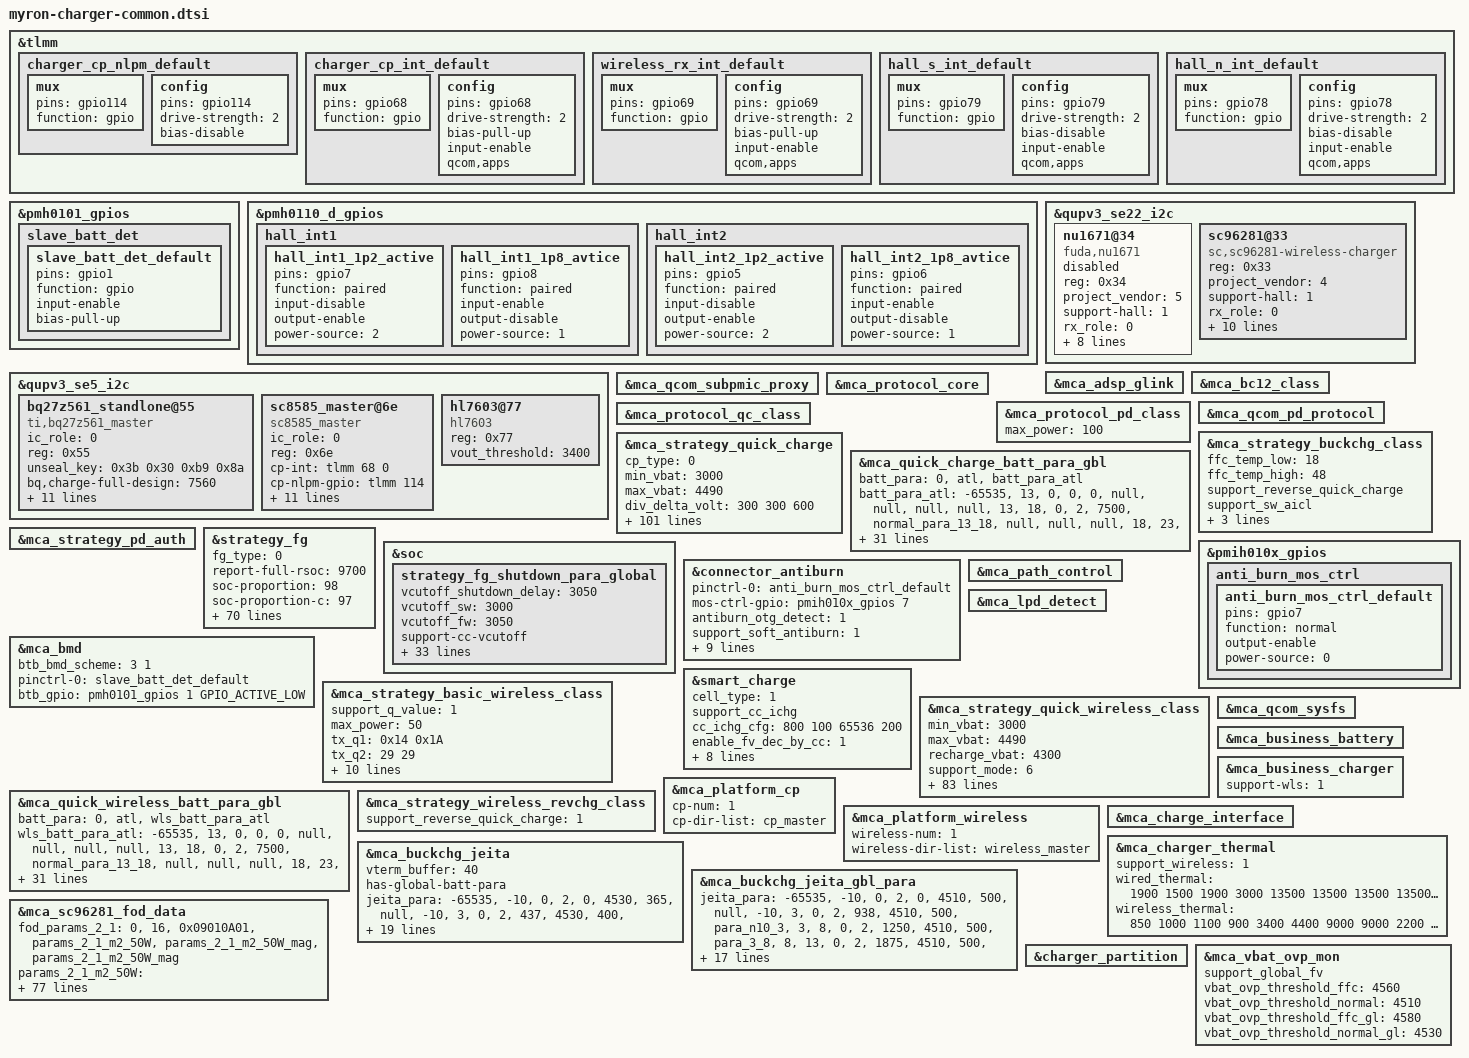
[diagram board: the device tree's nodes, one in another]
#include "mca.dtsi"

&tlmm {
	charger_cp_nlpm_default: charger_cp_nlpm_default {
		mux {
			pins = "gpio114";
			function = "gpio";
		};
		config {
			pins = "gpio114";
			drive-strength = <2>;   /* 2 mA */
			bias-disable;
		};
	};

	charger_cp_int_default: charger_cp_int_default {
		mux {
			pins = "gpio68";
			function = "gpio";
		};
		config {
			pins = "gpio68";
			drive-strength = <2>;   /* 2 mA */
			bias-pull-up;
			input-enable;
			qcom,apps;
		};
	};

	wireless_rx_int_default: wireless_rx_int_default {
		mux {
			pins = "gpio69";
			function = "gpio";
		};

		config {
			pins = "gpio69";
			drive-strength = <2>;
			bias-pull-up;
			input-enable;
			qcom,apps;
		};
	};

	hall_s_int_default: hall_s_int_default {
		mux {
			pins = "gpio79";
			function = "gpio";
		};

		config {
			pins = "gpio79";
			drive-strength = <2>;
			bias-disable;
			input-enable;
			qcom,apps;
		};
	};

	hall_n_int_default: hall_n_int_default {
		mux {
			pins = "gpio78";
			function = "gpio";
		};

		config {
			pins = "gpio78";
			drive-strength = <2>;
			bias-disable;
			input-enable;
			qcom,apps;
		};
	};

};

&pmh0101_gpios {
	slave_batt_det {
		slave_batt_det_default: slave_batt_det_default {
			pins = "gpio1";
			function = "gpio";
			input-enable;
			bias-pull-up;
		};
	};
};

&pmh0110_d_gpios {
	hall_int1 {
		hall_int1_1p2_active: hall_int1_1p2_active {
			pins = "gpio7";
			function = "paired";
			input-disable;
			output-enable;
			power-source = <2>; /* 1.2v */
		};

		hall_int1_1p8_avtice:hall_int1_1p8_avtice {
			pins = "gpio8";
			function = "paired";
			input-enable;
			output-disable;
			power-source = <1>; /* 1.8v */
		};
	};

	hall_int2 {
		hall_int2_1p2_active: hall_int2_1p2_active {
			pins = "gpio5";
			function = "paired";
			input-disable;
			output-enable;
			power-source = <2>; /* 1.2v */
		};

		hall_int2_1p8_avtice:hall_int2_1p8_avtice {
			pins = "gpio6";
			function = "paired";
			input-enable;
			output-disable;
			power-source = <1>; /* 1.8v */
		};
	};
};


&qupv3_se5_i2c {
	status = "ok";
	#address-cells = <1>;
	#size-cells = <0>;
	bq27z561_standlone@55 {
		compatible = "ti,bq27z561_master";
		ic_role = <0>;
		reg = <0x55>;
		unseal_key = /bits/ 8 <0x3b 0x30 0xb9 0x8a>;
		bq,charge-full-design = <7560>;
		soh_th = <92>;
		cycle_th = <400>;
		cycle_step = <50>;
		resistance-id = <100000>;
		support_batt_manager_4p0;
		base_termv = <3030>;
		base_termv_gl = <3200>;
		delta_soh_compesation = <
			0 0
			50 2
			100 5
			150 7
			200 9
			250 12
			300 15
			350 18
			400 18
			450 18
			500 18>;
		delta_soh_compesation_gl = <
			0 0
			50 1
			100 2
			150 4
			200 5
			250 5
			300 5
			350 5
			400 5
			450 5
			500 5>;
		status = "ok";
	};

	sc8585_master@6e {
		compatible = "sc8585_master";
		status = "ok";
		ic_role = <0>;
		reg = <0x6e>;
		cp-int= <&tlmm 68 0>;
		cp-nlpm-gpio = <&tlmm 114 0x00>;
		pinctrl-names = "default";
		pinctrl-0 = <&charger_cp_nlpm_default>, <&charger_cp_int_default>;
		bat-ovp-threshold = <4700>;
		bat-ovp-alarm-threshold = <4650>;
		bus-ovp-threshold = <21000 12000 6000>;
		usb-ovp-threshold = <21000 14000 7500>;
		bus-ocp-threshold = <5000 5500 5000>;
		wpc-ovp-threshold = <21000>;
		out-ovp-threshold = <5000>;
		pmid2-uvp-threshold = <350 350 100>;
		pmid2-ovp-threshold = <600>;
	};

	hl7603@77 {
		compatible = "hl7603";
		reg = <0x77>;
		vout_threshold = <3400>;
	};
};

&qupv3_se22_i2c {
	status = "ok";
	#address-cells = <1>;
	#size-cells = <0>;

	nu1671@34 {
		status = "disabled";
		compatible = "fuda,nu1671";
		reg = <0x34>;
		project_vendor = <5>;
		support-hall = <1>;
		rx_role = <0>;
		fw_version_index = <0>;
		pinctrl-names = "default";
		pinctrl-0 = <&wireless_rx_int_default>, <&hall_s_int_default>, <&hall_n_int_default>;
		rx-int = <&tlmm 69 0x00>;
		pwr-det-int = <&tlmm 57 0x00>;
		sleep-rx-gpio = <&tlmm 200 0x00>;
		hall-s-int = <&tlmm 79 0x00>;
		hall-n-int = <&tlmm 78 0x00>;
	};

	sc96281@33 {
		compatible = "sc,sc96281-wireless-charger";
		reg = <0x33>;
		project_vendor = <4>;
		support-hall = <1>;
		rx_role = <0>;
		fw_version_index = <1>;
		pinctrl-names = "default";
		pinctrl-0 = <&wireless_rx_int_default>, <&hall_s_int_default>, <&hall_n_int_default>,
					<&hall_int1_1p2_active>, <&hall_int1_1p8_avtice>,
					<&hall_int2_1p2_active>, <&hall_int2_1p8_avtice>;
		rx-int = <&tlmm 69 0x00>;
		pwr-det-int = <&tlmm 57 0x00>;
		sleep-rx-gpio = <&tlmm 200 0x00>;
		hall-s-int = <&tlmm 79 0x00>;
		hall-n-int = <&tlmm 78 0x00>;
	};
};

&mca_adsp_glink {
	status = "ok";
};

&mca_bc12_class {
	status = "ok";
};

&mca_qcom_subpmic_proxy {
	status = "ok";
};

&mca_protocol_core {
	status = "ok";
};

&mca_protocol_pd_class {
	status = "ok";
	max_power = <100>;
};

&mca_qcom_pd_protocol {
	status = "ok";
};

&mca_protocol_qc_class {
	status = "ok";
};


&mca_strategy_buckchg_class {
	status = "ok";
	ffc_temp_low = <18>;
	ffc_temp_high = <48>;
	support_reverse_quick_charge;
	support_sw_aicl;
	support_revchg_screenon;
	support_pps_100w = <3>;
	pd_authing_default_icl;
};

&mca_strategy_quick_charge {
	status = "ok";
	cp_type = <0>;
	min_vbat = <3000>;
	max_vbat = <4490>;
	div_delta_volt = <300 300 600>;
	div_single_curr = <4500 11000 18400>;
	div_max_curr = <5000 12000 18400>;
	non_mi_pps_max_curr = <4500 11000 18400>;
	support_mode = <6>;
	has-global-batt-para;
	support_cp_vfc = <1>;
	real_curr_max = <17500>;
	support_monitor_current = <17600>;
	curr_monitor_time_s = <120>;
	support_cancel_compensation;
	max_vbat_threshold = <4580>;
	en_buck_parallel_chg = <1>;
	buck_icl_fcc_curr = <1000 3000>;
	buck_en_th = <13000 2500>;
	buck_dis_th = <13000 3850>;

	/* volt_ratio, cur_gap, vbat_gap, vstep_ratio */
	vstep_para =
		"1", "300", "2000", "0", "2",
		"2", "300", "2000", "0", "4",
		"4", "300", "8000", "0", "25",
		"4", "300", "4000", "20", "17",
		"4", "300", "2000", "10", "8",
		"4", "300", "1200", "10", "5",
		"4", "300", "800", "0", "2",
		"1", "800", "2000", "0", "2",
		"2", "800", "2000", "0", "4",
		"4", "800", "8000", "0", "10",
		"4", "800", "6000", "0", "5",
		"4", "800", "4000", "0", "2";

	batt_para =
		"0", "atl", "batt_para_atl",
		"0", "coslight", "batt_para_cos";
	/* temp_low, temp_high, low_hys, high_hys, max_curr, normal_para, ffc_para, normal_stage, ffc_stage */
	batt_para_atl =
		"-65535", "13", "0", "0", "0", "null", "null", "null", "null",
		"13", "18", "0", "2", "4374", "normal_para_atl_13_18", "null", "null", "null",
		"18", "23", "0", "1", "12400", "normal_para_atl_18_23", "ffc_para_atl_18_23", "null", "ffc_stage_atl_18_23",
		"23", "35", "0", "0", "18400", "normal_para_atl_23_35", "ffc_para_atl_23_35", "null", "ffc_stage_atl_23_35",
		"35", "40", "1", "0", "18400", "normal_para_atl_35_40", "ffc_para_atl_35_40", "null", "ffc_stage_atl_35_40",
		"40", "48", "1", "0", "18400", "normal_para_atl_40_48", "ffc_para_atl_40_48", "null", "ffc_stage_atl_40_48",
		"48", "65535", "2", "0", "0", "null", "null", "null", "null";

	/* volt, curr_max, curr_min */
	normal_para_atl_13_18 =
		"4200", "4374", "2916",
		"4525", "2916", "365";

	normal_para_atl_18_23 =
		"4250", "12400", "8748",
		"4505", "8748", "365";
	ffc_para_atl_18_23 =
		"4250", "12400", "10935",
		"4500", "10935", "8748",
		"4555", "8748", "1094";
	ffc_stage_atl_18_23 = <0 0 0 0 0 0>;

	normal_para_atl_23_35 =
		"4190", "18400", "8748",
		"4505", "8748", "365";
	ffc_para_atl_23_35 =
		"4190", "18400", "12400",
		"4290", "12400", "10935",
		"4500", "10935", "8748",
		"4555", "8748", "1458";
	ffc_stage_atl_23_35 = <0 1 0 0 0 0 0 0>;

	normal_para_atl_35_40 =
		"4190", "18400", "8748",
		"4495", "8748", "365";
	ffc_para_atl_35_40 =
		"4190", "18400", "12400",
		"4290", "12400", "10935",
		"4500", "10935", "8748",
		"4555", "8748", "2333";
	ffc_stage_atl_35_40 = <0 1 0 0 0 0 0 0>;

	normal_para_atl_40_48 =
		"4190", "18400", "8748",
		"4485", "8748", "365";
	ffc_para_atl_40_48 =
		"4190", "18400", "12400",
		"4290", "12400", "10935",
		"4500", "10935", "8748",
		"4555", "8748", "3208";
	ffc_stage_atl_40_48 = <0 1 0 0 0 0 0 0>;

	batt_para_cos =
		"-65535", "13", "0", "0", "0", "null", "null", "null", "null",
		"13", "18", "0", "2", "4386", "normal_para_cos_13_18", "null", "null", "null",
		"18", "23", "0", "1", "12400", "normal_para_cos_18_23", "ffc_para_cos_18_23", "null", "ffc_stage_cos_18_23",
		"23", "35", "0", "0", "18400", "normal_para_cos_23_35", "ffc_para_cos_23_35", "null", "ffc_stage_cos_23_35",
		"35", "40", "1", "0", "18400", "normal_para_cos_35_40", "ffc_para_cos_35_40", "null", "ffc_stage_cos_35_40",
		"40", "48", "1", "0", "18400", "normal_para_cos_40_48", "ffc_para_cos_40_48", "null", "ffc_stage_cos_40_48",
		"48", "65535", "2", "0", "0", "null", "null", "null", "null";
	/* volt, curr_max, curr_min */
	normal_para_cos_13_18 =
		"4200", "4386", "2924",
		"4525", "2924", "366";

	normal_para_cos_18_23 =
		"4250", "12400", "8772",
		"4505", "8772", "366";
	ffc_para_cos_18_23 =
		"4250", "12400", "10965",
		"4500", "10965", "8772",
		"4555", "8772", "810";
	ffc_stage_cos_18_23 = <0 0 0 0 0 0>;

	normal_para_cos_23_35 =
		"4290", "18400", "8772",
		"4505", "8772", "366";
	ffc_para_cos_23_35 =
		"4290", "18400", "12400",
		"4350", "12400", "10965",
		"4500", "10965", "8772",
		"4555", "8772", "1023";
	ffc_stage_cos_23_35 = <0 1 0 0 0 0 0 0>;

	normal_para_cos_35_40 =
		"4290", "18400", "8772",
		"4495", "8772", "366";
	ffc_para_cos_35_40 =
		"4290", "18400", "12400",
		"4350", "12400", "10965",
		"4500", "10965", "8772",
		"4555", "8772", "1608";
	ffc_stage_cos_35_40 = <0 1 0 0 0 0 0 0>;

	normal_para_cos_40_48 =
		"4290", "18400", "8772",
		"4485", "8772", "366";
	ffc_para_cos_40_48 =
		"4290", "18400", "12400",
		"4350", "12400", "10965",
		"4500", "10965", "8772",
		"4555", "8772", "2339";
	ffc_stage_cos_40_48 = <0 1 0 0 0 0 0 0>;
};

&mca_quick_charge_batt_para_gbl {
	batt_para =
		"0", "atl", "batt_para_atl";
	/* temp_low, temp_high, low_hys, high_hys, max_curr, normal_para, ffc_para, normal_stage, ffc_stage */
	batt_para_atl =
		"-65535", "13", "0", "0", "0", "null", "null", "null", "null",
		"13", "18", "0", "2", "7500", "normal_para_13_18", "null", "null", "null",
		"18", "23", "0", "1", "12500", "normal_para_18_23", "null", "null", "null",
		"23", "35", "0", "0", "18000", "normal_para_23_35", "ffc_para_23_35", "null", "ffc_stage_23_35",
		"35", "40", "1", "0", "18000", "normal_para_35_40", "ffc_para_35_40", "null", "ffc_stage_35_40",
		"40", "48", "1", "0", "18000", "normal_para_40_48", "ffc_para_40_48", "null", "ffc_stage_40_48",
		"48", "65535", "2", "0", "0", "null", "null", "null", "null";

	/* volt, curr_max, curr_min */
	normal_para_13_18 =
		"4200", "7500", "6250",
		"4505", "6250", "500";

	normal_para_18_23 =
		"4200", "12500", "9375",
		"4505", "9375", "500";

	normal_para_23_35 =
		"4150", "18000", "7500",
		"4505", "7500", "500";
	ffc_para_23_35 =
		"4150", "18000", "12400",
		"4350", "12400", "11250",
		"4400", "11250", "9375",
		"4500", "9375", "7500",
		"4555", "7500", "2500";
	ffc_stage_23_35 = <0 0 0 0 0 0 0 0 0 0>;

	normal_para_35_40 =
		"4150", "18000", "7500",
		"4475", "7500", "500";
	ffc_para_35_40 =
		"4150", "18000", "12400",
		"4350", "12400", "11250",
		"4400", "11250", "9375",
		"4500", "9375", "7500",
		"4555", "7500", "3562";
	ffc_stage_35_40 = <0 0 0 0 0 0 0 0 0 0>;

	normal_para_40_48 =
		"4150", "18000", "7500",
		"4465", "7500", "500";
	ffc_para_40_48 =
		"4150", "18000", "12400",
		"4350", "12400", "11250",
		"4400", "11250", "9375",
		"4500", "9375", "7500",
		"4555", "7500", "5000";
	ffc_stage_40_48 = <0 0 0 0 0 0 0 0 0 0>;
};

&mca_strategy_pd_auth {
	status = "ok";
};

&strategy_fg {
	status = "ok";
	fg_type = <0>;
	report-full-rsoc = <9700>;
	soc-proportion = <98>;
	soc-proportion-c = <97>;
	support-pnc;
	support-vpack-low-shutdown;
	has_global_shutdown_para;
	vcutoff_shutdown_delay = <3030>;
	vcutoff_sw = <2980>;
	vcutoff_fw = <3030>;
	vterm_delta = <7>;

	support-cc-vcutoff;
	/* temp_low, temp_high, low_temp_hys, high_temp_hys, vterm_para_name */
	cc_vcutoff_cfg =
		"-65535", "-6", "0", "2", "cc_para0",
		"-6", "0", "2", "2", "cc_para1",
		"0", "10", "2", "2", "cc_para2",
		"10", "60", "2", "0", "cc_para3",
		"60", "65535", "2", "0", "cc_para4";
	/* cycle_count, vterm_fw, vterm_shutdown_delay, vempty */
	cc_para0 =
		"400", "2650", "2600", "2500",
		"800", "2700", "2650", "2600",
		"1200", "2850", "2800", "2750",
		"65535", "2950", "2900", "2850";
	cc_para1 =
		"400", "2700", "2650", "2600",
		"800", "2850", "2800", "2750",
		"1200", "2950", "2900", "2850",
		"65535", "3050", "3000", "2950";
	cc_para2 =
		"400", "2850", "2850", "2800",
		"800", "2950", "2950", "2900",
		"1200", "3000", "3000", "2950",
		"65535", "3100", "3100", "3050";
	cc_para3 =
		"400", "3030", "3030", "2980",
		"800", "3130", "3130", "3080",
		"1200", "3200", "3200", "3150",
		"65535", "3260", "3260", "3210";
	cc_para4 =
		"65535", "3260", "3260", "3210";

	support-dod-vcutoff-v2;
	weight = <20 18 15>;
	/* temp_low, temp_high, low_temp_hys, high_temp_hys, vterm_para_name */
	dod_vcutoff_cfg =
		"-65535", "-6", "0", "2", "dod_para0",
		"-6", "0", "2", "2", "dod_para1",
		"0", "10", "2", "2", "dod_para2",
		"10", "60", "2", "0", "dod_para3",
		"60", "65535", "2", "0", "dod_para4";
	/* dod_count, vterm_fw, vterm_shutdown_delay, vempty */
	dod_para0 =
		"79", "2650", "2600", "2500",
		"159", "2700", "2650", "2600",
		"413", "2850", "2800", "2750",
		"1050", "2950", "2900", "2850",
		"65535", "3050", "3000", "2950";
	dod_para1 =
		"79", "2700", "2650", "2600",
		"159", "2850", "2800", "2750",
		"413", "2950", "2900", "2850",
		"1050", "3050", "3000", "2950",
		"65535", "3150", "3100", "3050";
	dod_para2 =
		"79", "2850", "2850", "2800",
		"159", "2950", "2950", "2900",
		"413", "3000", "3000", "2950",
		"1050", "3100", "3100", "3050",
		"65535", "3200", "3200", "3150";
	dod_para3 =
		"79", "3030", "3030", "2980",
		"159", "3130", "3130", "3080",
		"413", "3200", "3200", "3150",
		"1050", "3260", "3260", "3210",
		"65535", "3310", "3310", "3260";
	dod_para4 =
		"65535", "3310", "3310", "3260";

	adapt_power = <100>;
	model-name = "P11U_7560mah_100w";
	model-name-global = "P11U_6500mah_100w";
	support_full_design_gl;
	charge-full-design = <7560>;
	capacity_comp = <0>;
	capacity_comp_gl = <0>;
	support_dynamic_capacity_comp;
	support_dtpt = <1>;
	charge-full-design-gl = <6500>;
	fg_hightemp_vterm = <4200>;
	support-lossless-rechg = <1>;
	lossless_rechg_cfg = <18 47 90>;
	support_normal_force_full;
	normal_force_full_hys = <116>;
	suppot_RSOC_0_smooth = <1>;
	smooth_temp_unit = <0 150>; //15℃
	smooth_curr_unit = <0 300000 600000 1000000 >;
	smooth_vol_offset = <0x80000000 0 100 200 300 >;
	dischg_smooth_low_temp_unit = <
		10 10 10 10
		20 10 10 10
		40 20 10 10
		80 40 30 20
		150 80 70 50 >;
	dischg_smooth_high_temp_unit = <
		10 10 10 10
		30 20 10 10
		60 40 20 10
		150 70 50 40
		200 150 100 70 >;
	extreme_cold_temp_compemsation =
		"100", "50", "50",
		"100", "350", "65",
		"350", "350", "80",
		"2147483647", "150", "100";
};

&soc {
	strategy_fg_shutdown_para_global {
		vcutoff_shutdown_delay = <3050>;
		vcutoff_sw = <3000>;
		vcutoff_fw = <3050>;
		support-cc-vcutoff;
		/* temp_low, temp_high, low_temp_hys, high_temp_hys, vterm_para_name */
		cc_vcutoff_cfg =
			"-65535", "-6", "0", "2", "cc_para0",
			"-6", "0", "2", "2", "cc_para1",
			"0", "10", "2", "2", "cc_para2",
			"10", "60", "2", "0", "cc_para3",
			"60", "65535", "2", "0", "cc_para4";
		/* cycle_count, vterm_fw, vterm_shutdown_delay, vempty */
		cc_para0 =
			"600", "2900", "2850", "2800",
			"1200", "2900", "2850", "2800",
			"65535", "3000", "2950","2900";
		cc_para1 =
			"600", "2900", "2850", "2800",
			"1200", "2900", "2850","2800",
			"65535", "3050", "3000", "2950";
		cc_para2 =
			"600", "2950", "2950", "2900",
			"1200", "3050", "3050", "3000",
			"65535", "3150", "3150", "3100";
		cc_para3 =
			"12", "3050", "3050", "3000",
			"600", "3200", "3200", "3150",
			"1200", "3280", "3280", "3230",
			"65535", "3350", "3350", "3300";
		cc_para4 =
			"65535", "3350", "3350", "3300";
		support-dod-vcutoff;
		weight = <30 21 14>;
		/* temp_low, temp_high, low_temp_hys, high_temp_hys, vterm_para_name */
		dod_vcutoff_cfg =
			"-65535", "-6", "0", "2", "dod_para0",
			"-6", "0", "2", "2", "dod_para1",
			"0", "10", "2", "2", "dod_para2",
			"10", "60", "2", "0", "dod_para3",
			"60", "65535", "2", "0", "dod_para4";
		/* dod_count, vterm_fw, vterm_shutdown_delay, vempty */
		dod_para0 =
			"94", "2900", "2850", "2800",
			"281", "2900", "2850", "2800",
			"563", "3000", "2950", "2900",
			"65535", "3050", "3000", "2950";
		dod_para1 =
			"94", "2900", "2850", "2800",
			"281", "2900", "2850", "2800",
			"563", "3050", "3000", "2950",
			"65535", "3200", "3150", "3100";
		dod_para2 =
			"94", "2950", "2950", "2900",
			"281", "3050", "3050", "3000",
			"563", "3150", "3150", "3100",
			"65535", "3300", "3300", "3250";
		dod_para3 =
			"30", "3050", "3050", "3000",
			"94", "3200", "3200", "3150",
			"281", "3280", "3280", "3230",
			"563", "3350", "3350", "3300",
			"65535", "3400", "3400", "3380";
		dod_para4 =
			"65535", "3400", "3400", "3380";
	};
};

&pmih010x_gpios {
	anti_burn_mos_ctrl {
		anti_burn_mos_ctrl_default: anti_burn_mos_ctrl_default {
			pins = "gpio7";
			function = "normal";
			output-enable;
			//drive-strength = <2>;
			power-source = <0>;
		};
	};
};

&connector_antiburn {
	status = "ok";
	pinctrl-names = "default";
	pinctrl-0 = <&anti_burn_mos_ctrl_default>;
	mos-ctrl-gpio = <&pmih010x_gpios 7 0>;
	antiburn_otg_detect = <1>;
	support_soft_antiburn = <1>;
	support_hw_antiburn = <1>;
	use_double_ntc = <1>;
	monitor_interval = <1000>;
	thermal-zone-name = "conn_therm";
	thermal-zone-name2 = "conn_therm2";
	max_temp_increase_rate = <4>; /*ntc temperature increase speed per second.*/
	otg_boost_src = <2>; /* BOOST_SRC_EXTERNAL */
	en_src = <0>; /* OTG_EN_BOOST */
	thermal-board-temp-name = "board_sensor_therm";
};

&mca_bmd {
	status = "ok";
	btb_bmd_scheme = <3 1>;
	pinctrl-names = "default";
	pinctrl-0 = <&slave_batt_det_default>;
	btb_gpio = <&pmh0101_gpios 1 GPIO_ACTIVE_LOW>;
};

&smart_charge {
	status = "ok";
	cell_type = <1>;
	support_cc_ichg;
	/* cyclecount delta_ichg*/
	cc_ichg_cfg = <
		800 100
		65536 200>;
	enable_fv_dec_by_cc = <1>;
	smart_bypass_support = <1>;
	smart_bypass_entry_soc = <40>;
	smart_bypass_high_lmt_cfg = <
		(-100) 150 5 5 4500
		151 200 5 5 4500
		201	250	5 5 4500
		251	300	5 5 3500
		301	370	5 5 2500
		371	800	5 5 1000>;
	smart_bypass_med_lmt_cfg = <
		(-100) 150 5 5 18400
		151	200	5 5 18400
		201	250	5 5 18400
		251	300	5 5 8000
		301	370	5 5 5000
		371	800	5 5 2000>;
	smart_bypass_low_lmt_cfg = <
		(-100) 150 5 5 18400
		151	200	5 5 18400
		201	250	5 5 18400
		251	300	5 5 9000
		301	370	5 5 5000
		371	800	5 5 3000>;
};

&mca_path_control {
	status = "ok";
};

&mca_lpd_detect {
	status = "ok";
};

&mca_strategy_basic_wireless_class {
	status = "ok";
	support_q_value = <1>;
	max_power = <50>;
	/* low_inductance_tx_50w, low_inductance_tx_80w */
	tx_q1 = /bits/ 8 <0x14 0x1A>;
	tx_q2 = <29 29>;
	rx_max_iout = <2650 2650>;
	wls_vdd_src = <2>;
	ffc_temp_low = <15>;
	ffc_temp_high = <48>;
	support-hall = <1>;

	support-dynamic-cp = <1>;
	dynamic-cp-uuid = <0x09010A01>;
	dynamic-cp-min-tx-adapter = <14>;
	dynamic-cp-4to2-threshold = <6000>;
	dynamic-cp-2-1-max-fcc = <9200>;
};

&mca_strategy_quick_wireless_class {
	status = "ok";
	min_vbat = <3000>;
	max_vbat = <4490>;
	recharge_vbat = <4300>;
	support_mode = <6>;
	div_single_curr = <0 9200 9200>;
	div_max_curr = <0 9200 9200>;
	has-global-batt-para;
	support-hall = <1>;
	batt_para =
		"0", "atl", "wls_batt_para_atl",
		"0", "coslight", "wls_batt_para_cos";
	/* temp_low, temp_high, low_temp_hys, high_temp_hys, max_current, volt_para_name stage_para_name*/
	wls_batt_para_atl =
		"-65535", "13", "0", "0", "0", "null", "null", "null", "null",
		"13", "18", "0", "2", "4374", "normal_para_atl_13_18", "null", "null", "null",
		"18", "23", "0", "1", "12400", "normal_para_atl_18_23", "ffc_para_atl_18_23", "null", "ffc_stage_atl_18_23",
		"23", "35", "0", "0", "17600", "normal_para_atl_23_35", "ffc_para_atl_23_35", "null", "ffc_stage_atl_23_35",
		"35", "40", "1", "0", "17600", "normal_para_atl_35_40", "ffc_para_atl_35_40", "null", "ffc_stage_atl_35_40",
		"40", "48", "1", "0", "17600", "normal_para_atl_40_48", "ffc_para_atl_40_48", "null", "ffc_stage_atl_40_48",
		"48", "65535", "2", "0", "0", "null", "null", "null", "null";

	/* volt, curr_max, curr_min */
	normal_para_atl_13_18 =
		"4200", "4374", "2916",
		"4520", "2916", "1300";

	normal_para_atl_18_23 =
		"4250", "12400", "8748",
		"4500", "8748", "1300";
	ffc_para_atl_18_23 =
		"4250", "12400", "10935",
		"4500", "10935", "8748",
		"4500", "8748", "1300";
	ffc_stage_atl_18_23 = <0 1 0 1 0 1 0 1 0 1>;

	normal_para_atl_23_35 =
		"4190", "17600", "8748",
		"4500", "8748", "1300";
	ffc_para_atl_23_35 =
		"4190", "17600", "12400",
		"4290", "12400", "10935",
		"4500", "10935", "8748",
		"4500", "8748", "1300";
	ffc_stage_atl_23_35 = <0 1 0 1 0 1 0 1 0 1>;

	normal_para_atl_35_40 =
		"4190", "17600", "8748",
		"4490", "8748", "1300";
	ffc_para_atl_35_40 =
		"4190", "17600", "12400",
		"4290", "12400", "10935",
		"4490", "10935", "1300";
	ffc_stage_atl_35_40 = <0 1 0 1 0 1 0 1 0 1>;

	normal_para_atl_40_48 =
		"4190", "17600", "8748",
		"4480", "8748", "1300";
	ffc_para_atl_40_48 =
		"4190", "17600", "12400",
		"4290", "12400", "10935",
		"4480", "10930", "1300";
	ffc_stage_atl_40_48 = <0 1 0 1 0 1 0 1 0 1>;

	wls_batt_para_cos =
		"-65535", "13", "0", "0", "0", "null", "null", "null", "null",
		"13", "18", "0", "2", "4386", "normal_para_cos_13_18", "null", "null", "null",
		"18", "23", "0", "1", "12400", "normal_para_cos_18_23", "ffc_para_cos_18_23", "null", "ffc_stage_cos_18_23",
		"23", "35", "0", "0", "17600", "normal_para_cos_23_35", "ffc_para_cos_23_35", "null", "ffc_stage_cos_23_35",
		"35", "40", "1", "0", "17600", "normal_para_cos_35_40", "ffc_para_cos_35_40", "null", "ffc_stage_cos_35_40",
		"40", "48", "1", "0", "17600", "normal_para_cos_40_48", "ffc_para_cos_40_48", "null", "ffc_stage_cos_40_48",
		"48", "65535", "2", "0", "0", "null", "null", "null", "null";
	/* volt, curr_max, curr_min */
	normal_para_cos_13_18 =
		"4200", "4386", "2924",
		"4520", "2924", "1300";

	normal_para_cos_18_23 =
		"4250", "12400", "8772",
		"4500", "8772", "1300";
	ffc_para_cos_18_23 =
		"4250", "12400", "10965",
		"4500", "10965", "8772",
		"4500", "8772", "1300";
	ffc_stage_cos_18_23 = <0 1 0 1 0 1 0 1 0 1>;

	normal_para_cos_23_35 =
		"4290", "17600", "8772",
		"4500", "8772", "1300";
	ffc_para_cos_23_35 =
		"4290", "17600", "12400",
		"4350", "12400", "10965",
		"4500", "10965", "8772",
		"4500", "8772", "1300";
	ffc_stage_cos_23_35 = <0 1 0 1 0 1 0 1 0 1>;

	normal_para_cos_35_40 =
		"4290", "17600", "8772",
		"4490", "8772", "1300";
	ffc_para_cos_35_40 =
		"4290", "17600", "12400",
		"4350", "12400", "10965",
		"4490", "10965", "1300";
	ffc_stage_cos_35_40 = <0 1 0 1 0 1 0 1 0 1>;

	normal_para_cos_40_48 =
		"4290", "17600", "8772",
		"4480", "8772", "1300";
	ffc_para_cos_40_48 =
		"4290", "17600", "12400",
		"4350", "12400", "10965",
		"4480", "10965", "1300";
	ffc_stage_cos_40_48 = <0 1 0 1 0 1 0 1 0 1>;

	vstep_para =
		"1", "2000", "2",
		"2", "4000", "25",
		"2", "3000", "25",
		"2", "2000", "4",
		"4", "4000", "25",
		"4", "3000", "25",
		"4", "2000", "6",
		"4", "1000", "3",
		"4", "500", "2",
		"4", "200", "1";
};

&mca_quick_wireless_batt_para_gbl {
	batt_para =
		"0", "atl", "wls_batt_para_atl";
	/* temp_low, temp_high, low_temp_hys, high_temp_hys, max_current, volt_para_name stage_para_name*/
	wls_batt_para_atl =
		"-65535", "13", "0", "0", "0", "null", "null", "null", "null",
		"13", "18", "0", "2", "7500", "normal_para_13_18", "null", "null", "null",
		"18", "23", "0", "1", "12500", "normal_para_18_23", "null", "null", "null",
		"23", "35", "0", "0", "17600", "normal_para_23_35", "ffc_para_23_35", "null", "ffc_stage_23_35",
		"35", "40", "1", "0", "17600", "normal_para_35_40", "ffc_para_35_40", "null", "ffc_stage_35_40",
		"40", "48", "1", "0", "17600", "normal_para_40_48", "ffc_para_40_48", "null", "ffc_stage_40_48",
		"48", "65535", "0", "0", "0", "null", "null", "null", "null";

	/* volt, curr_max, curr_min */
	normal_para_13_18 =
		"4200", "7500", "6250",
		"4500", "6250", "1300";

	normal_para_18_23 =
		"4200", "12500", "9375",
		"4500", "9375", "1300";

	normal_para_23_35 =
		"4150", "17600", "7500",
		"4480", "7500", "1300";
	ffc_para_23_35 =
		"4150", "17600", "12400",
		"4350", "12400", "11250",
		"4400", "11250", "9375",
		"4480", "9375", "1300";
	ffc_stage_23_35 = <0 1 0 1 0 1 0 1 0 1>;

	normal_para_35_40 =
		"4150", "17600", "7500",
		"4470", "7500", "1300";
	ffc_para_35_40 =
		"4150", "17600", "12400",
		"4350", "12400", "11250",
		"4400", "11250", "9375",
		"4470", "9375", "1300";
	ffc_stage_35_40 = <0 1 0 1 0 1 0 1 0 1>;

	normal_para_40_48 =
		"4150", "17600", "7500",
		"4460", "7500", "1300";
	ffc_para_40_48 =
		"4150", "17600", "12400",
		"4350", "12400", "11250",
		"4400", "11250", "9375",
		"4460", "9375", "1300";
	ffc_stage_40_48 = <0 1 0 1 0 1 0 1 0 1>;
};

&mca_strategy_wireless_revchg_class {
	status = "ok";
	support_reverse_quick_charge = <1>;
};

&mca_qcom_sysfs {
	status = "ok";
};

&mca_business_battery {
	status = "ok";
};

&mca_business_charger {
	support-wls = <1>;
	status = "ok";
};

&mca_platform_cp {
	status = "ok";
	cp-num = <1>;
	cp-dir-list = "cp_master";
};

&mca_platform_wireless {
	status = "ok";
	wireless-num = <1>;
	wireless-dir-list = "wireless_master";
};

&mca_charge_interface {
	status = "ok";
};

&mca_charger_thermal {
	status = "ok";
	support_wireless = <1>;
	/* 5v_in 9v_in 5v_ichg 9v_ichg div1_single div1_multi div2_single div2_multi div4_single div4_multi*/
	wired_thermal = <
		1900 1500 1900 3000 13500 13500 13500 13500 13500 13500 /* level 1 */
		1900 1500 1900 3000 11000 11000 11000 11000 11000 11000 /* level 2 */
		1900 1500 1900 3000 9000  9000  9000  9000  9000  9000  /* level 3 */
		1900 1450 1900 3000 8000  8000  8000  8000  8000  8000  /* level 4 */
		1900 1400 1900 3000 7000  7000  7000  7000  7000  7000  /* level 5 */
		1900 1350 1900 2800 6000  6000  6000  6000  6000  6000  /* level 6 */
		1900 1300 1900 2600 5000  5000  5000  5000  5000  5000  /* level 7 */
		1900 1150 1900 2310 4000  4000  4000  4000  4000  4000  /* level 8 */
		1700 1100 1700 2200 3500  3500  3500  3500  3500  3500  /* level 9 */
		1600 1000 1600 2000 3000  3000  3000  3000  3000  3000  /* level 10 */
		1400 900  1500 2000 2500  2500  2500  2500  2500  2500  /* level 11 */
		1200 850  1500 2000 2000  2000  2000  2000  2000  2000  /* level 12 */
		1100 750  1500 1500 1500  1500  1500  1500  1500  1500  /* level 13 */
		1100 650  1000 1000 1000  1000  1000  1000  1000  1000  /* level 14 */
		1100 600  500  500  500   500   500   500   500   500   /* level 15 */
	>;
	/* bpp_in bpp_qc2 bpp_qc3 epp_in cp_20w cp_30w cp_50w cp_80w voice_box magnet_30w xiaomi_car */
	wireless_thermal = <
		850 1000 1100 900 3400 4400 9000 9000 2200 4400 9000  /* level 1 */
		850 1000 1100 750 3200 4200 8000 8000 2200 4200 8000  /* level 2 */
		850 1000 1100 650 2200 3400 7000 7000 1000 3400 7000  /* level 3 */
		700 1000 1100 650 1800 2800 6000 6000 1000 2800 6000  /* level 4 */
		700 1000  700 650 1500 2600 5000 5000  800 2600 5000  /* level 5 */
		500 1000  700 650 1300 2200 4000 4000  800 2200 4000  /* level 6 */
		500  700  600 400 1100 2200 3500 3500  700 2200 3500  /* level 7 */
		500  700  600 400 1000 1800 3000 3000  700 1800 3000  /* level 8 */
		500  500  500 300  800 1100 2500 2500  600 1100 2500  /* level 9 */
		400  500  500 300  700 1000 2000 2000  600 1000 2000  /* level 10 */
		400  500  500 250  600  800 1500 1500  500  800 1500  /* level 11 */
		400  500  500 250  500  700 1000 1000  500  700 1000  /* level 12 */
		300  500  500 250  500  600  800  800  400  600  800   /* level 13 */
		300  400  400 200  400  500  500  500  400  500  500   /* level 14 */
		300  300  300 150  300  400  400  400  300  400  400   /* level 15 */
	>;
};

&mca_buckchg_jeita {
	status = "ok";
	vterm_buffer = <40>;
	has-global-batt-para;
	/* temp_low, temp_high, low_temp_hys, high_temp_hys, max_current, vterm, iterm volt_para_name */
	jeita_para =
		"-65535", "-10", "0", "2", "0", "4530", "365", "null",
		"-10", "3", "0", "2", "437", "4530", "400", "para_n10_3",
		"3", "8", "0", "2", "1094", "4530", "365", "para_3_8",
		"8", "13", "0", "2", "2187", "4530", "365", "para_8_13",
		"13", "18", "0", "2", "4000", "4530", "365", "para_13_18",
		"18", "23", "0", "1", "4000", "4510", "365", "null",
		"23", "35", "0", "0", "4000", "4510", "365", "null",
		"35", "40", "1", "0", "4000", "4500", "365", "null",
		"40", "48", "1", "0", "4000", "4490", "365", "null",
		"48", "55", "2", "0", "3645", "4080", "365", "null",
		"55", "65535", "2", "2", "0", "4080", "365", "null";
	para_n10_3 =
		"4530", "437";
	para_3_8 =
		"4200", "1094",
		"4530", "729";
	para_8_13 =
		"4200", "2187",
		"4530", "1458";
	para_13_18 =
		"4200", "4374",
		"4530", "2916";
	jeita_para_ffc =
		"18", "23", "0", "1", "4000", "4560", "1114", "null",
		"23", "35", "0", "0", "4000", "4560", "1458", "null",
		"35", "40", "1", "0", "4000", "4560", "2333", "null",
		"40", "48", "1", "0", "4000", "4560", "3208", "null",
		"48", "55", "2", "0", "3645", "4080", "365", "null",
		"55", "65535", "2", "2", "0", "4080", "365", "null";
};

&mca_buckchg_jeita_gbl_para {
	/* temp_low, temp_high, low_temp_hys, high_temp_hys, max_current, vterm, iterm volt_para_name */
	jeita_para =
		"-65535", "-10", "0", "2", "0", "4510", "500", "null",
		"-10", "3", "0", "2", "938", "4510", "500", "para_n10_3",
		"3", "8", "0", "2", "1250", "4510", "500", "para_3_8",
		"8", "13", "0", "2", "1875", "4510", "500", "para_8_13",
		"13", "18", "0", "2", "4000", "4510", "500", "para_13_18",
		"18", "23", "0", "1", "4000", "4510", "500", "para_18_23",
		"23", "35", "0", "0", "4000", "4490", "500", "null",
		"35", "40", "1", "0", "4000", "4480", "500", "null",
		"40", "48", "1", "0", "4000", "4470", "500", "null",
		"48", "55", "2", "0", "3125", "4080", "500", "null",
		"55", "65535", "2", "2", "0", "4080", "500", "null";
	para_n10_3 =
		"4200", "938",
		"4510", "625";
	para_3_8 =
		"4200", "1250",
		"4510", "938";
	para_8_13 =
		"4200", "1875",
		"4510", "1250";
	para_13_18 =
		"4200", "4000",
		"4510", "4000";
	para_18_23 =
		"4200", "4000",
		"4510", "4000";
	jeita_para_ffc =
		"23", "35", "0", "0", "4000", "4560", "2812", "null",
		"35", "40", "1", "0", "4000", "4560", "4062", "null",
		"40", "48", "1", "0", "4000", "4560", "6062", "null",
		"48", "55", "2", "0", "3125", "4080", "500", "null",
		"55", "65535", "2", "2", "0", "4080", "500", "null";
};

&mca_sc96281_fod_data
{
	fod_params_2_1 =
		"0", "16", "0x09010A01", "params_2_1_m2_50W", "params_2_1_m2_50W_mag", "params_2_1_m2_50W_mag";

	params_2_1_m2_50W = /bits/ 8 <
		142 50
		142 50
		142 50
		142 50
		142 50
		133 25
		133 20
		132 20
		131 20
		124 30
		124 30
		126 25
		126 25
		127 25
		128 20
		128 30
	>;

	params_2_1_m2_50W_mag = /bits/ 8 <
		160 70
		155 50
		150 50
		150 50
		140 40
		137 35
		134 30
		130 30
		129 30
		129 30
		128 40
		127 40
		127 40
		127 45
		127 45
		127 45
	>;

	params_m2_50W = /bits/ 8 <
		142 50
		142 50
		142 50
		142 50
		142 50
		160 86
		140 70
		138 52
		140 62
		140 62
		140 62
		144 32
		142 50
		142 50
		142 20
		140 30
	>;

	params_m2_50W_mag = /bits/ 8 <
		153 60
		149 55
		149 50
		148 60
		153 50
		153 65
		153 70
		152 50
		144 40
		142 40
		141 40
		139 45
		138 55
		138 55
		138 60
		138 60
	>;

	params_double_coil_30W = /bits/ 8 <
		150 52
		150 20
		150 10
		149 0
		148 10
		140 10
		150 20
		159 40
		138 0
		140 5
		143 0
		141 10
		141 0
		142 0
		142 0
		142 0
	>;

	params_redmi_disc_30W = /bits/ 8 <
		150 82
		150 60
		150 40
		149 40
		148 25
		140 10
		150 20
		150 20
		138 40
		140 35
		140 35
		141 35
		141 25
		142 0
		142 0
		142 0
	>;

	params_white_stand_30W = /bits/ 8 <
		150 82
		150 60
		150 40
		149 40
		148 40
		140 15
		150 20
		150 25
		138 50
		140 45
		140 45
		141 45
		141 35
		142 0
		142 0
		142 0
	>;

	params_l2_50W = /bits/ 8 <
		150 82
		150 30
		150 20
		149 20
		148 20
		140 30
		147 0
		150 0
		138 30
		140 15
		140 15
		141 15
		141 5
		140 0
		139 0
		139 0
	>;

	params_k1_80W = /bits/ 8 <
		155 55
		155 55
		150 45
		149 45
		144 40
		140 35
		140 35
		140 35
		140 35
		140 40
		141 45
		141 45
		141 45
		141 45
		141 52
		141 52
	>;

	params_k1_80W_mag = /bits/ 8 <
		155 40
		155 35
		150 30
		149 25
		148 25
		140 30
		150 10
		150 10
		138 30
		140 20
		140 20
		141 20
		141 15
		141 15
		141 5
		141 5
	>;

	params_zimi_20W = /bits/ 8 <
		155 55
		155 45
		150 45
		149 40
		148 40
		135 50
		135 50
		135 50
		135 50
		135 50
		135 50
		135 50
		135 50
		135 50
		135 50
		135 50
	>;

	params_multcoil_20W = /bits/ 8 <
		155 65
		155 60
		150 60
		149 60
		148 60
		135 65
		135 65
		135 65
		135 65
		135 65
		135 65
		135 65
		135 65
		135 65
		135 65
		135 65
	>;

	params_moving_20W = /bits/ 8 <
		155 45
		155 30
		150 30
		149 30
		148 30
		135 40
		135 40
		135 40
		135 40
		135 40
		135 40
		135 40
		135 40
		135 40
		135 40
		135 40
	>;

	params_k8_100W = /bits/ 8 <
		155 55
		155 40
		150 40
		149 30
		148 35
		140 45
		150 20
		150 15
		138 50
		140 40
		140 40
		141 45
		141 45
		141 45
		141 40
		141 40
	>;

	params_k8_100W_mag = /bits/ 8 <
		155 60
		155 40
		150 30
		149 25
		148 25
		140 25
		150 5
		150 2
		138 30
		140 20
		140 20
		141 15
		141 5
		141 5
		141 5
		141 5
	>;

	params_white_stand_30W_mag = /bits/ 8 <
		155 75
		155 75
		150 70
		149 55
		148 40
		140 40
		150 10
		150 10
		138 30
		140 20
		140 20
		141 20
		141 15
		141 15
		141 5
		141 15
	>;

	params_double_coil_30W_mag = /bits/ 8 <
		155 40
		155 25
		150 20
		149 15
		148 25
		140 30
		150 10
		150 0
		138 30
		140 20
		140 20
		141 20
		141 15
		141 5
		141 5
		141 5
	>;

	params_j1s_55W = /bits/ 8 <
		150 82
		150 30
		150 20
		149 20
		148 20
		140 30
		147 0
		150 0
		138 30
		140 15
		140 15
		141 15
		141 5
		140 0
		139 0
		139 0
	>;

	params_j1s_55W_mag = /bits/ 8 <
		155 60
		155 55
		150 50
		149 35
		148 35
		140 30
		150 10
		150 10
		138 30
		140 20
		140 20
		141 20
		140 0
		140 0
		139 0
		139 0
	>;

	params_redmi_disc_30W_mag = /bits/ 8 <
		155 60
		155 45
		150 20
		149 15
		148 25
		140 20
		150 0
		150 0
		138 25
		140 20
		140 10
		141 10
		141 5
		141 0
		141 0
		141 0
	>;

	params_white_20W = /bits/ 8 <
		155 45
		155 30
		150 30
		149 30
		148 30
		140 30
		150 10
		150 0
		138 30
		140 20
		140 20
		141 20
		141 15
		141 5
		141 5
		141 5
	>;

	params_white_20W_mag = /bits/ 8 <
		155 45
		155 30
		150 30
		149 30
		148 30
		140 30
		150 10
		150 0
		138 30
		140 20
		140 20
		141 20
		141 15
		141 5
		141 5
		141 5
	>;

	params_black_vertical_30W_mag = /bits/ 8 <
		155 45
		155 30
		150 30
		149 30
		148 30
		140 30
		150 10
		150 0
		138 30
		140 20
		140 20
		141 20
		141 15
		141 5
		141 5
		141 5
	>;

	params_zimi_car_50W = /bits/ 8 <
		155 45
		155 30
		150 30
		149 30
		148 30
		135 40
		135 40
		135 40
		135 40
		135 40
		135 40
		135 40
		135 40
		135 40
		135 40
		135 40
	>;

	params_zimi_car_50W_mag = /bits/ 8 <
		155 45
		155 30
		150 30
		149 30
		148 30
		140 30
		150 10
		150 0
		138 30
		140 20
		140 20
		141 20
		141 15
		141 5
		141 5
		141 5
	>;

	params_magnet_black_car_30W_mag = /bits/ 8 <
		155 45
		155 30
		150 30
		149 30
		148 30
		140 30
		150 10
		150 0
		138 30
		140 20
		140 20
		141 20
		141 15
		141 5
		141 5
		141 5
	>;

	params_p11u_trx_rev_22P5W_mag = /bits/ 8 <
		155 60
		155 45
		150 50
		149 35
		148 45
		140 40
		150 40
		150 40
		138 40
		140 40
		140 40
		141 40
		141 40
		141 40
		141 40
		141 40
	>;

	params_low_inductance_80w = /bits/ 8 <
		125 40
		125 40
		125 40
		125 40
		127 40
		131 35
		125 40
		126 45
		122 40
		122 40
		122 40
		121 40
		120 40
		120 45
		120 50
		120 50
	>;

	params_low_inductance_80w_mag = /bits/ 8 <
		110 20
		111 30
		113 30
		115 30
		116 40
		110 30
		110 20
		111 25
		111 25
		112 25
		112 25
		112 25
		112 30
		112 30
		113 40
		113 45
	>;

	params_magnet_2in1_30W = /bits/ 8 <
		140 50
		140 50
		143 50
		145 50
		141 50
		138 40
		138 40
		137 45
		137 45
		137 45
		137 50
		137 50
		137 50
		138 55
		138 55
		138 55
	>;

	params_black_fan_mag = /bits/ 8 <
		110 20
		111 30
		113 30
		115 30
		116 40
		110 30
		110 20
		111 25
		111 25
		112 25
		112 25
		112 25
		112 30
		112 30
		113 40
		113 45
	>;

	params_black_short_mike_mag = /bits/ 8 <
		110 20
		111 30
		113 30
		115 30
		116 40
		110 30
		110 20
		111 25
		111 25
		112 25
		112 25
		112 25
		112 30
		112 30
		113 40
		113 45
	>;

	params_magnet_2in1_30W_mag = /bits/ 8 <
		140 50
		140 50
		143 50
		145 50
		141 50
		138 40
		138 40
		137 45
		137 45
		137 45
		137 50
		137 50
		137 50
		138 55
		138 55
		138 55
	>;

	params_power_bank_30W = /bits/ 8 <
		155 45
		155 30
		150 30
		149 30
		148 30
		140 30
		150 10
		150 0
		138 30
		140 20
		140 20
		141 20
		141 15
		141 5
		141 5
		141 5
	>;

	params_power_bank_30W_mag = /bits/ 8 <
		155 45
		155 30
		150 30
		149 30
		148 30
		140 30
		150 10
		150 0
		138 30
		140 20
		140 20
		141 20
		141 15
		141 5
		141 5
		141 5
	>;

	params_zimi_car_20W = /bits/ 8 <
		155 45
		155 30
		150 30
		149 30
		148 30
		135 40
		135 40
		135 40
		135 40
		135 40
		135 40
		135 40
		135 40
		135 40
		135 40
		135 40
	>;

	params_zimi_car_20W_mag = /bits/ 8 <
		155 45
		155 30
		150 30
		149 30
		148 30
		135 40
		135 40
		135 40
		135 40
		135 40
		135 40
		135 40
		135 40
		135 40
		135 40
		135 40
	>;

	params_bluetooth_30W = /bits/ 8 <
		155 45
		155 30
		150 30
		149 30
		148 30
		135 40
		135 40
		135 40
		135 40
		135 40
		135 40
		135 40
		135 40
		135 40
		135 40
		135 40
	>;

	params_bluetooth_30W_mag = /bits/ 8 <
		155 45
		155 30
		150 30
		149 30
		148 30
		135 40
		135 40
		135 40
		135 40
		135 40
		135 40
		135 40
		135 40
		135 40
		135 40
		135 40
	>;
};

&charger_partition {
	status = "ok";
};

&mca_vbat_ovp_mon {
	status = "ok";
	support_global_fv;
	vbat_ovp_threshold_ffc = <4560>;
	vbat_ovp_threshold_normal = <4510>;
	vbat_ovp_threshold_ffc_gl = <4580>;
	vbat_ovp_threshold_normal_gl = <4530>;
};
